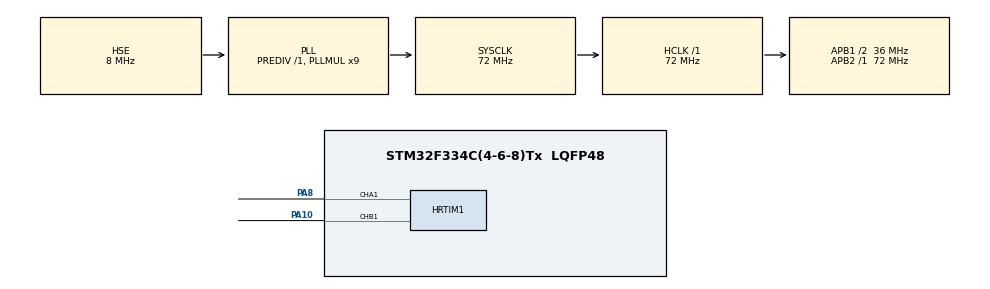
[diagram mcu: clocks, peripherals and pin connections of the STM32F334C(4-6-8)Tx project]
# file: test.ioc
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HRTIM1.CompareUnit1-Output_TA1=HRTIM_COMPAREUNIT_1
HRTIM1.CompareUnit1-Output_TB1=HRTIM_COMPAREUNIT_1
HRTIM1.CompareValue1-Output_TA1=720
HRTIM1.CompareValue1-Output_TB1=720
HRTIM1.NumberResetSource1-Output_TA1=1
HRTIM1.NumberResetSource1-Output_TB1=1
HRTIM1.NumberSetSource1-Output_TA1=1
HRTIM1.NumberSetSource1-Output_TB1=1
HRTIM1.Periode_TA=1440
HRTIM1.Periode_TB=1440
HRTIM1.PreloadEnable-Output_TA1=HRTIM_PRELOAD_ENABLED
HRTIM1.PreloadEnable-Output_TB1=HRTIM_PRELOAD_ENABLED
HRTIM1.PrescalerRatio_TA=HRTIM_PRESCALERRATIO_DIV1
HRTIM1.PrescalerRatio_TB=HRTIM_PRESCALERRATIO_MUL32
HRTIM1.RepetitionUpdate-Output_TB1=HRTIM_UPDATEONREPETITION_ENABLED
HRTIM1.ResetOutput1_Source1-Output_TA1=HRTIM_OUTPUTRESET_TIMCMP1
HRTIM1.ResetOutput1_Source1-Output_TB1=HRTIM_OUTPUTRESET_TIMCMP1
HRTIM1.SetOutput1_Source1-Output_TA1=HRTIM_OUTPUTSET_TIMPER
HRTIM1.SetOutput1_Source1-Output_TB1=HRTIM_OUTPUTSET_TIMPER
Mcu.Family=STM32F3
Mcu.Name=STM32F334C(4-6-8)Tx
Mcu.Package=LQFP48
Mcu.UserConstants=PWM_PERIOD,1440
NVIC.PriorityGroup=NVIC_PRIORITYGROUP_4
PA10.Mode=Output_TB1
PA10.Signal=HRTIM1_CHB1
PA8.GPIO_PuPd=GPIO_PULLUP
PA8.Mode=Output_TA1
PA8.Signal=HRTIM1_CHA1
PF0\ /\ OSC_IN.Mode=HSE-External-Oscillator
PF0\ /\ OSC_IN.Signal=RCC_OSC_IN
PF1\ /\ OSC_OUT.Mode=HSE-External-Oscillator
PF1\ /\ OSC_OUT.Signal=RCC_OSC_OUT
ProjectManager.HeapSize=0x200
ProjectManager.StackSize=0x400
ProjectManager.TargetToolchain=STM32CubeIDE
RCC.AHBFreq_Value=72000000
RCC.APB1CLKDivider=RCC_HCLK_DIV2
RCC.APB1Freq_Value=36000000
RCC.APB1TimFreq_Value=72000000
RCC.APB2Freq_Value=72000000
RCC.APB2TimFreq_Value=72000000
RCC.CortexFreq_Value=72000000
RCC.HCLKFreq_Value=72000000
RCC.HRTIMSelection=RCC_HRTIM1CLK_PLLCLK
RCC.HSE_VALUE=8000000
RCC.HSI_VALUE=8000000
RCC.LSE_VALUE=32768
RCC.PLLMUL=RCC_PLL_MUL9
RCC.PLLSourceVirtual=RCC_PLLSOURCE_HSE
RCC.SYSCLKFreq_VALUE=72000000
RCC.SYSCLKSourceVirtual=RCC_SYSCLKSOURCE_PLLCLK
board=custom

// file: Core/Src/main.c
/* USER CODE BEGIN Header */
/**
  ******************************************************************************
  * @file           : main.c
  * @brief          : Main program body
  ******************************************************************************
  * @attention
  *
  * Copyright (c) 2025 STMicroelectronics.
  * All rights reserved.
  *
  * This software is licensed under terms that can be found in the LICENSE file
  * in the root directory of this software component.
  * If no LICENSE file comes with this software, it is provided AS-IS.
  *
  ******************************************************************************
  */
/* USER CODE END Header */
#include "main.h"

/* USER CODE BEGIN Includes */
#include "stdint.h"
#include "math.h"
/* USER CODE END Includes */

/* USER CODE BEGIN PD */
#define BUFFER_LEN 128
/* USER CODE END PD */

HRTIM_HandleTypeDef hhrtim1;

void SystemClock_Config(void);
static void MX_GPIO_Init(void);
static void MX_HRTIM1_Init(void);

/* USER CODE BEGIN 0 */

// DMA buffer: interleaved CMP1 values for Timer A
uint16_t dma_buffer[BUFFER_LEN];

/**
 * @brief  Fill dma_buffer with sin/cos waveforms at 50 Hz
 */
void generate_dma_buffer(void)
{
    const float dt = 1.0f / 100000.0f; // PWM timebase at 100 kHz
    for (int i = 0; i < BUFFER_LEN; i++) {
        float t    = i * dt;
        // normalize sine/cosine to [0..1]
        float sinv = (sinf(2.0f * M_PI * 50.0f * t) + 1.0f) * 0.5f;
        //float cosv = (cosf(2.0f * M_PI * 50.0f * t) + 1.0f) * 0.5f;
        // scale to PWM_PERIOD
        uint16_t cmp1 = (uint16_t)(sinv * PWM_PERIOD + 0.5f);
        //uint16_t cmp2 = (uint16_t)(cosv * PWM_PERIOD + 0.5f);
        dma_buffer[i]     = cmp1;
        //dma_buffer[2 * i + 1] = cmp2;
    }
}
/* USER CODE END 0 */

int main(void)
{

  /* MCU Configuration--------------------------------------------------------*/

  /* Reset of all peripherals, Initializes the Flash interface and the Systick. */
  HAL_Init();

  /* Configure the system clock */
  SystemClock_Config();

  /* Initialize all configured peripherals */
  MX_GPIO_Init();
  MX_HRTIM1_Init();
  /* USER CODE BEGIN 2 */
//  // 1) Prepare waveform data
//      generate_dma_buffer();
//
//      // 2) Configure Timer A outputs (in MX_HRTIM1_Init)
//      //    - TA1: Set on period, Reset on CMP1
//      //    - TA2: Set on period, Reset on CMP2
//      //    ==> see comments in MX_HRTIM1_Init
//
//      // 3) Enable DMA Burst for CMP1 & CMP2 on Timer A
//      HAL_HRTIM_BurstDMAConfig(&hhrtim1,
//                                HRTIM_TIMERINDEX_TIMER_A,
//                                HRTIM_BURSTDMA_CMP1);
//
//      // 4) Start circular DMA transfer (one BUFFER_LEN; 2 halfwords per event)
//      HAL_HRTIM_BurstDMATransfer(&hhrtim1,
//                                 HRTIM_TIMERINDEX_TIMER_A,
//                                 (uint32_t)dma_buffer,
//                                 BUFFER_LEN);
//
//      // 5) Launch Timer A with DMA
//      HAL_HRTIM_WaveformCountStart_DMA(&hhrtim1,
//                                         HRTIM_TIMERID_TIMER_A);
//
//
//      // 6) Enable PWM outputs TA1 and TA2
//      HAL_HRTIM_WaveformOutputStart(&hhrtim1,
//                                     HRTIM_OUTPUT_TA1);

      // 7) Now PWM runs endlessly; main loop can be idle
  /* USER CODE END 2 */

  /* Infinite loop */
  /* USER CODE BEGIN WHILE */
  HAL_HRTIM_WaveformCountStart(&hhrtim1, HRTIM_TIMERID_TIMER_B);
  volatile uint32_t cnt = HRTIM1->sTimerxRegs[0].CNTxR;
  for (volatile int i=0;i<1000;i++); // коротка пауза
  volatile uint32_t cnt2 = HRTIM1->sTimerxRegs[0].CNTxR;
  HAL_HRTIM_WaveformOutputStart(&hhrtim1, HRTIM_OUTPUT_TB1);
  while (1)
  {
	 // __WFI();
    /* USER CODE END WHILE */

  }
}

void SystemClock_Config(void)
{
  RCC_OscInitTypeDef RCC_OscInitStruct = {0};
  RCC_ClkInitTypeDef RCC_ClkInitStruct = {0};
  RCC_PeriphCLKInitTypeDef PeriphClkInit = {0};

  /** Initializes the RCC Oscillators according to the specified parameters
  * in the RCC_OscInitTypeDef structure.
  */
  RCC_OscInitStruct.OscillatorType = RCC_OSCILLATORTYPE_HSE;
  RCC_OscInitStruct.HSEState = RCC_HSE_ON;
  RCC_OscInitStruct.HSEPredivValue = RCC_HSE_PREDIV_DIV1;
  RCC_OscInitStruct.HSIState = RCC_HSI_ON;
  RCC_OscInitStruct.PLL.PLLState = RCC_PLL_ON;
  RCC_OscInitStruct.PLL.PLLSource = RCC_PLLSOURCE_HSE;
  RCC_OscInitStruct.PLL.PLLMUL = RCC_PLL_MUL9;
  if (HAL_RCC_OscConfig(&RCC_OscInitStruct) != HAL_OK)
  {
    Error_Handler();
  }

  /** Initializes the CPU, AHB and APB buses clocks
  */
  RCC_ClkInitStruct.ClockType = RCC_CLOCKTYPE_HCLK|RCC_CLOCKTYPE_SYSCLK
                              |RCC_CLOCKTYPE_PCLK1|RCC_CLOCKTYPE_PCLK2;
  RCC_ClkInitStruct.SYSCLKSource = RCC_SYSCLKSOURCE_PLLCLK;
  RCC_ClkInitStruct.AHBCLKDivider = RCC_SYSCLK_DIV1;
  RCC_ClkInitStruct.APB1CLKDivider = RCC_HCLK_DIV2;
  RCC_ClkInitStruct.APB2CLKDivider = RCC_HCLK_DIV1;

  if (HAL_RCC_ClockConfig(&RCC_ClkInitStruct, FLASH_LATENCY_2) != HAL_OK)
  {
    Error_Handler();
  }
  PeriphClkInit.PeriphClockSelection = RCC_PERIPHCLK_HRTIM1;
  PeriphClkInit.Hrtim1ClockSelection = RCC_HRTIM1CLK_PLLCLK;
  if (HAL_RCCEx_PeriphCLKConfig(&PeriphClkInit) != HAL_OK)
  {
    Error_Handler();
  }
}

static void MX_HRTIM1_Init(void)
{

  HRTIM_TimeBaseCfgTypeDef pTimeBaseCfg = {0};
  HRTIM_TimerCfgTypeDef pTimerCfg = {0};
  HRTIM_CompareCfgTypeDef pCompareCfg = {0};
  HRTIM_OutputCfgTypeDef pOutputCfg = {0};

  hhrtim1.Instance = HRTIM1;
  hhrtim1.Init.HRTIMInterruptResquests = HRTIM_IT_NONE;
  hhrtim1.Init.SyncOptions = HRTIM_SYNCOPTION_NONE;
  if (HAL_HRTIM_Init(&hhrtim1) != HAL_OK)
  {
    Error_Handler();
  }
  if (HAL_HRTIM_DLLCalibrationStart(&hhrtim1, HRTIM_CALIBRATIONRATE_14) != HAL_OK)
  {
    Error_Handler();
  }
  if (HAL_HRTIM_PollForDLLCalibration(&hhrtim1, 10) != HAL_OK)
  {
    Error_Handler();
  }
  pTimeBaseCfg.Period = 1440;
  pTimeBaseCfg.RepetitionCounter = 0x00;
  pTimeBaseCfg.PrescalerRatio = HRTIM_PRESCALERRATIO_DIV1;
  pTimeBaseCfg.Mode = HRTIM_MODE_CONTINUOUS;
  if (HAL_HRTIM_TimeBaseConfig(&hhrtim1, HRTIM_TIMERINDEX_TIMER_A, &pTimeBaseCfg) != HAL_OK)
  {
    Error_Handler();
  }
  pTimerCfg.InterruptRequests = HRTIM_TIM_IT_NONE;
  pTimerCfg.DMARequests = HRTIM_TIM_DMA_NONE;
  pTimerCfg.DMASrcAddress = 0x0000;
  pTimerCfg.DMADstAddress = 0x0000;
  pTimerCfg.DMASize = 0x1;
  pTimerCfg.HalfModeEnable = HRTIM_HALFMODE_DISABLED;
  pTimerCfg.StartOnSync = HRTIM_SYNCSTART_DISABLED;
  pTimerCfg.ResetOnSync = HRTIM_SYNCRESET_DISABLED;
  pTimerCfg.DACSynchro = HRTIM_DACSYNC_NONE;
  pTimerCfg.PreloadEnable = HRTIM_PRELOAD_ENABLED;
  pTimerCfg.UpdateGating = HRTIM_UPDATEGATING_INDEPENDENT;
  pTimerCfg.BurstMode = HRTIM_TIMERBURSTMODE_MAINTAINCLOCK;
  pTimerCfg.RepetitionUpdate = HRTIM_UPDATEONREPETITION_DISABLED;
  pTimerCfg.PushPull = HRTIM_TIMPUSHPULLMODE_DISABLED;
  pTimerCfg.FaultEnable = HRTIM_TIMFAULTENABLE_NONE;
  pTimerCfg.FaultLock = HRTIM_TIMFAULTLOCK_READWRITE;
  pTimerCfg.DeadTimeInsertion = HRTIM_TIMDEADTIMEINSERTION_DISABLED;
  pTimerCfg.DelayedProtectionMode = HRTIM_TIMER_A_B_C_DELAYEDPROTECTION_DISABLED;
  pTimerCfg.UpdateTrigger = HRTIM_TIMUPDATETRIGGER_NONE;
  pTimerCfg.ResetTrigger = HRTIM_TIMRESETTRIGGER_NONE;
  pTimerCfg.ResetUpdate = HRTIM_TIMUPDATEONRESET_DISABLED;
  if (HAL_HRTIM_WaveformTimerConfig(&hhrtim1, HRTIM_TIMERINDEX_TIMER_A, &pTimerCfg) != HAL_OK)
  {
    Error_Handler();
  }
  pTimerCfg.RepetitionUpdate = HRTIM_UPDATEONREPETITION_ENABLED;
  if (HAL_HRTIM_WaveformTimerConfig(&hhrtim1, HRTIM_TIMERINDEX_TIMER_B, &pTimerCfg) != HAL_OK)
  {
    Error_Handler();
  }
  pCompareCfg.CompareValue = 720;
  if (HAL_HRTIM_WaveformCompareConfig(&hhrtim1, HRTIM_TIMERINDEX_TIMER_A, HRTIM_COMPAREUNIT_1, &pCompareCfg) != HAL_OK)
  {
    Error_Handler();
  }
  pOutputCfg.Polarity = HRTIM_OUTPUTPOLARITY_HIGH;
  pOutputCfg.SetSource = HRTIM_OUTPUTSET_TIMPER;
  pOutputCfg.ResetSource = HRTIM_OUTPUTRESET_TIMCMP1;
  pOutputCfg.IdleMode = HRTIM_OUTPUTIDLEMODE_NONE;
  pOutputCfg.IdleLevel = HRTIM_OUTPUTIDLELEVEL_INACTIVE;
  pOutputCfg.FaultLevel = HRTIM_OUTPUTFAULTLEVEL_NONE;
  pOutputCfg.ChopperModeEnable = HRTIM_OUTPUTCHOPPERMODE_DISABLED;
  pOutputCfg.BurstModeEntryDelayed = HRTIM_OUTPUTBURSTMODEENTRY_REGULAR;
  if (HAL_HRTIM_WaveformOutputConfig(&hhrtim1, HRTIM_TIMERINDEX_TIMER_A, HRTIM_OUTPUT_TA1, &pOutputCfg) != HAL_OK)
  {
    Error_Handler();
  }
  if (HAL_HRTIM_WaveformOutputConfig(&hhrtim1, HRTIM_TIMERINDEX_TIMER_B, HRTIM_OUTPUT_TB1, &pOutputCfg) != HAL_OK)
  {
    Error_Handler();
  }
  pTimeBaseCfg.PrescalerRatio = HRTIM_PRESCALERRATIO_MUL32;
  if (HAL_HRTIM_TimeBaseConfig(&hhrtim1, HRTIM_TIMERINDEX_TIMER_B, &pTimeBaseCfg) != HAL_OK)
  {
    Error_Handler();
  }
  if (HAL_HRTIM_WaveformCompareConfig(&hhrtim1, HRTIM_TIMERINDEX_TIMER_B, HRTIM_COMPAREUNIT_1, &pCompareCfg) != HAL_OK)
  {
    Error_Handler();
  }
  HAL_HRTIM_MspPostInit(&hhrtim1);

}

static void MX_GPIO_Init(void)
{

  /* GPIO Ports Clock Enable */
  __HAL_RCC_GPIOF_CLK_ENABLE();
  __HAL_RCC_GPIOA_CLK_ENABLE();

}

void Error_Handler(void)
{
  __disable_irq();
  while (1)
  {
  }
}
